# BYS_B register map
Vendor: Texas Instruments
Peripheral module from a debugger description file (folder omap5430_ES2_PUBLIC).
Registers are 32-bit, access per field, reset 0x0 unless marked. A register's access mark holds for its fields unless they carry their own. Offsets are as the file gives them; lines under a group give offsets from that group; [hi:lo] are bit positions; {n}, {i} and the like mark numbered series; 'fields as' and 'values as' point back to an identical list; <NAME> marks a mode.

## BYS_B
0x00 BYS_HL_REVISION ro reset not defined — IP Revision Identifier (X.Y.R) Used by software to track features, bugs, and compatibility
  [31:0] REVISION — IP Revision
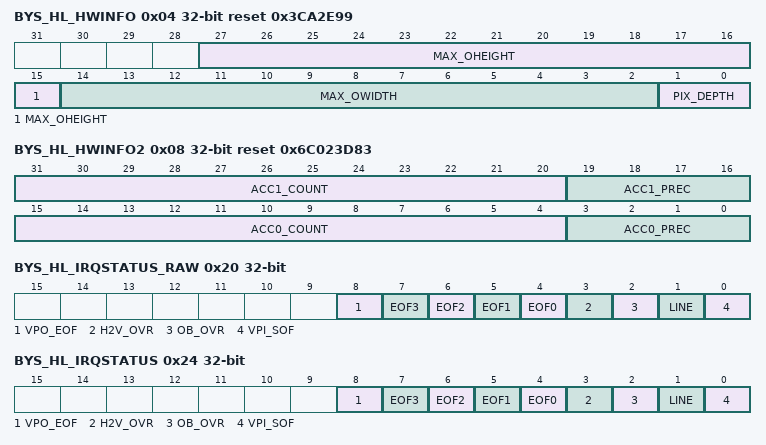
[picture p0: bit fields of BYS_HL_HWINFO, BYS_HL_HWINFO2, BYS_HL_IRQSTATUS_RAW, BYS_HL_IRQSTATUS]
0x04 BYS_HL_HWINFO ro reset 0x3CA2E99 — Information about the IP module's hardware configuration, i.e. typically the module's HDL generics (if any).
  [27:15] MAX_OHEIGHT — Maximum output height
  [14:2] MAX_OWIDTH — Maximum output width
  [1:0] PIX_DEPTH — Number of bits per pixel
    3=B16 (16); 2=B14 (14); 1=B12 (12); 0=B10 (10)
0x08 BYS_HL_HWINFO2 ro reset 0x6C023D83 — Information about the IP module's hardware configuration, i.e. typically the module's HDL generics (if any).
  [31:20] ACC1_COUNT — Number of entries = value*2
  [19:16] ACC1_PREC — Precision of accumulator 0 Number of Bits = value + 20
  [15:4] ACC0_COUNT — Number of entries = value*2
  [3:0] ACC0_PREC — Precision of accumulator 0 Number of Bits = value + 20
0x10 BYS_HL_SYSCONFIG — Clock management configuration
  [0] SOFTRESET rw — Software reset
    0=noaction; 1=reset (Initiate software reset); 1=pending (Reset (software or other) ongoing); 0=done (Reset done, no pending action)
0x20 BYS_HL_IRQSTATUS_RAW — Per-event raw interrupt status vector, line #0. Raw status is set even if event is not enabled.
  [all] fields
    1=pending (Event pending); 0=No event pending
  [8] VPO_EOF rw — Output video port end of frame event.
  [7] EOF3 rw
  [6] EOF2 rw
  [5] EOF1 rw — End of frame event of BSC pipe #1
  [4] EOF0 rw — End of frame event of BSC pipe #0
  [3] H2V_OVR rw — H2V FIFO overflow
  [2] OB_OVR rw — Output buffer overflow
  [1] LINE rw — Line event.
  [0] VPI_SOF rw — Start of frame event.
0x24 BYS_HL_IRQSTATUS — Per-event 'enabled' interrupt status vector, line #0. Enabled status isn't set unless event is enabled.
  [all] fields
    1=pending (Event pending); 0=noevent (No (enabled) event pending)
  [8] VPO_EOF rw — Output video port end of frame event.
  [7] EOF3 rw
  [6] EOF2 rw
  [5] EOF1 rw — End of frame event of BSC pipe #1
  [4] EOF0 rw — End of frame event of BSC pipe #0
  [3] H2V_OVR rw — H2V FIFO overflow
  [2] OB_OVR rw — Output buffer overflow
  [1] LINE rw — Line event.
  [0] VPI_SOF rw — Start of frame event.
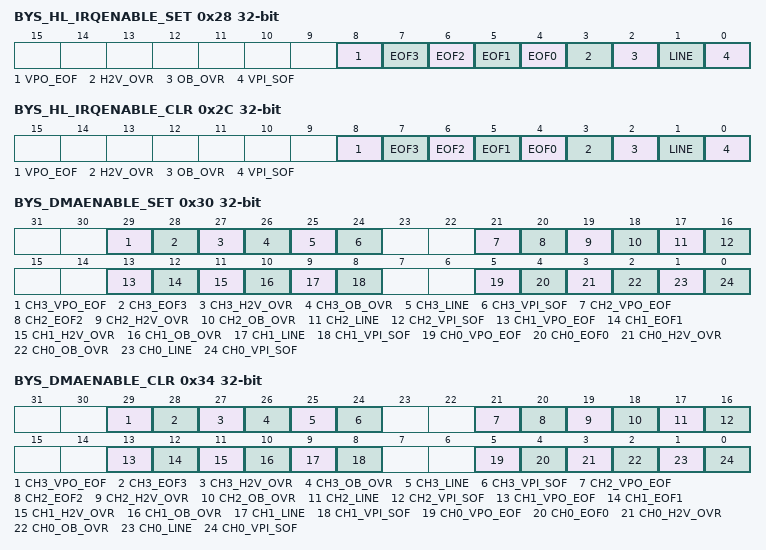
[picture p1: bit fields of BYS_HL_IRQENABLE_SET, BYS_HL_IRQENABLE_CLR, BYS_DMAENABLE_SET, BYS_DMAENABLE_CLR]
0x28 BYS_HL_IRQENABLE_SET access not given — Per-event interrupt enable bit vector Write 1 to set (enable interrupt). Readout equal to corresponding register.
  [all] fields
    0=noaction; 1=Enable interrupt; 1=enabled (Interrupt enabled); 0=disabled (Interrupt disabled (masked))
  [8] VPO_EOF — Output video port end of frame event. (access RW W1toSet)
  [7] EOF3 — (access RW W1toSet)
  [6] EOF2 — (access RW W1toSet)
  [5] EOF1 — End of frame event of BSC pipe #1 (access RW W1toSet)
  [4] EOF0 — End of frame event of BSC pipe #0 (access RW W1toSet)
  [3] H2V_OVR — H2V FIFO overflow (access RW W1toSet)
  [2] OB_OVR — Output buffer overflow (access RW W1toSet)
  [1] LINE — Line event (access RW W1toSet)
  [0] VPI_SOF — Start of frame event. (access RW W1toSet)
0x2C BYS_HL_IRQENABLE_CLR access not given — Per-event interrupt enable bit vector Write 1 to clear (disable interrupt). Readout equal to corresponding register.
  [all] fields
    0=noaction; 1=Disable interrupt; 1=enabled (Interrupt enabled); 0=disabled (Interrupt disabled (masked))
  [8] VPO_EOF — Output video port end of frame event. (access RW W1toClr)
  [7] EOF3 — (access RW W1toClr)
  [6] EOF2 — (access RW W1toClr)
  [5] EOF1 — End of frame event of BSC pipe #1 (access RW W1toClr)
  [4] EOF0 — End of frame event of BSC pipe #0 (access RW W1toClr)
  [3] H2V_OVR — H2V FIFO overflow (access RW W1toClr)
  [2] OB_OVR — Output buffer overflow. (access RW W1toClr)
  [1] LINE — Line event (access RW W1toClr)
  [0] VPI_SOF — Start of frame event. (access RW W1toClr)
0x30 BYS_DMAENABLE_SET — DMAREQUEST[0] Bits 7..0 DMAREQUEST[1] Bits 15..8 DMAREQUEST[2] Bits 23..16 DMAREQUEST[3] Bits 31..24 Write 1 to set (enable DMA request generation). Readout equal to corresponding register.
  [all] fields
    0=noaction; 1=Enable DMA; 1=enabled (DMA enabled); 0=disabled (DMA disabled)
  [29] CH3_VPO_EOF rw
  [28] CH3_EOF3 rw
  [27] CH3_H2V_OVR rw
  [26] CH3_OB_OVR rw
  [25] CH3_LINE rw
  [24] CH3_VPI_SOF rw
  [21] CH2_VPO_EOF rw
  [20] CH2_EOF2 rw
  [19] CH2_H2V_OVR rw
  [18] CH2_OB_OVR rw
  [17] CH2_LINE rw
  [16] CH2_VPI_SOF rw
  [13] CH1_VPO_EOF rw — Output video port end of frame event.
  [12] CH1_EOF1 rw — End of frame event of BSC pipe #1
  [11] CH1_H2V_OVR rw — H2V FIFO overflow
  [10] CH1_OB_OVR rw — Output buffer overflow.
  [9] CH1_LINE rw — Line event
  [8] CH1_VPI_SOF rw — Start of frame event.
  [5] CH0_VPO_EOF rw — Output video port end of frame event.
  [4] CH0_EOF0 rw — End of frame event of BSC pipe #0
  [3] CH0_H2V_OVR rw — H2V FIFO overflow
  [2] CH0_OB_OVR rw — Output buffer overflow.
  [1] CH0_LINE rw — Line event
  [0] CH0_VPI_SOF rw — Start of frame event.
0x34 BYS_DMAENABLE_CLR — DMAREQUEST[0] Bits 7..0 DMAREQUEST[1] Bits 15..8 DMAREQUEST[2] Bits 23..16 DMAREQUEST[3] Bits 31..24 Write 1 to clear (disable DMA request generation). Readout equal to corresponding register.
  [all] fields
    0=noaction; 1=enable (Disable DMA); 1=enabled (DMA enabled); 0=disabled (DMA disabled)
  [29] CH3_VPO_EOF rw
  [28] CH3_EOF3 rw
  [27] CH3_H2V_OVR rw
  [26] CH3_OB_OVR rw
  [25] CH3_LINE rw
  [24] CH3_VPI_SOF rw
  [21] CH2_VPO_EOF rw
  [20] CH2_EOF2 rw
  [19] CH2_H2V_OVR rw
  [18] CH2_OB_OVR rw
  [17] CH2_LINE rw
  [16] CH2_VPI_SOF rw
  [13] CH1_VPO_EOF rw — Output video port end of frame event.
  [12] CH1_EOF1 rw — End of frame event of BSC pipe #1
  [11] CH1_H2V_OVR rw — H2V FIFO overflow
  [10] CH1_OB_OVR rw — Output buffer overflow.
  [9] CH1_LINE rw — Line event
  [8] CH1_VPI_SOF rw — Start of frame event
  [5] CH0_VPO_EOF rw — Output video port end of frame event.
  [4] CH0_EOF0 rw — End of frame event of BSC pipe #0
  [3] CH0_H2V_OVR rw — H2V FIFO overflow
  [2] CH0_OB_OVR rw — Output buffer overflow.
  [1] CH0_LINE rw — Line event
  [0] CH0_VPI_SOF rw — Start of frame event
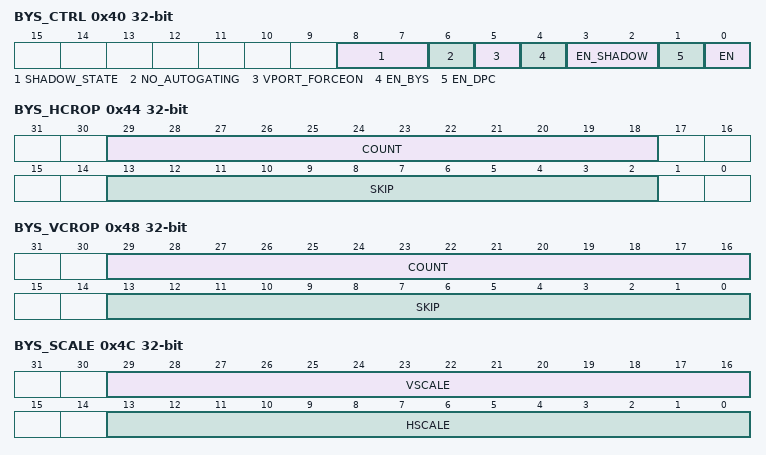
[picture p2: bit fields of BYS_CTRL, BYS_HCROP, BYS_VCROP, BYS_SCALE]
0x40 BYS_CTRL — Global control of the BYS module
  [8:7] SHADOW_STATE ro — Indicates the shadow register currently in use by the hardware. Register written by hardware. Software must check this before writing the BYS_CTRL register when BYS is active, so that a write into EN_SHADOW bit-field does not unintentially swap banks. Read 0x0: No shadowing. Hardware and software access bank 0. Read 0x1: No shadowing. Hardware and software access bank 1. Read 0x2: Shadowing. Hardware access bank 0 and software access bank 1. Read 0x3: Shadowing. Hardware access bank 1 and software access bank 0.
  [6] NO_AUTOGATING rw — Control internal autogating. ** DEBUG FEATURE **
    0=EN (Autogating enabled. This is the recommended behavior); 1=DIS (Autogating disabled Power consumption is increased. Only for debug purposes.)
  [5] VPORT_FORCEON rw — Controls gating of the output video port clock
    0=AUTO (Auto-gating. The video port clock is - enabled when pixels are sent - enabled 4 cycles before the 1st pixel is sent - disabled 4 pixels after the last pixel has been sent - disabled otherwise); 1=FREE (The pixel clock is free-running during blanking)
  [4] EN_BYS rw — Enable bayer scaler
    0=DISABLED (Disabled. Bayer scaler processing is bypassed (i.e. the output of the bayer scaler is the same than the bayer scaler input)); 1=ENABLED (Bayer scaler enabled)
  [3:2] EN_SHADOW rw — Controls register shadowing. Register written by software.
    0=OFF1 (No shadowing. Hardware and software access bank 0); 1=OFF2 (No shadowing. Hardware and software access bank 1); 3=ON2 (Shadowing. Hardware access bank 1 and software access bank 0.); 2=ON1 (Shadowing. Hardware access bank 0 and software access bank 1.)
  [1] EN_DPC rw — Enable defect pixel correction
    0=DIS (Defect pixel correction bypassed); 1=EN (Defect pixel correction enabled)
  [0] EN rw — Enable the BYS module
    0=DIS (Module disabled. Incoming pixels are ignored.); 1=EN (Enabled Incoming pixels will be processed.)
0x44 BYS_HCROP — Horizontal cropping settings. SKIP and COUNT positions must be multiples of 4 pixels.
  [29:18] COUNT rw — In steps of 4 pixels (i.e. write number of pixels to count divided by 4 into this register)
  [13:2] SKIP rw — In steps of 4 pixels (i.e. write number of pixels to skip divided by 4 into this register)
0x48 BYS_VCROP
  [29:16] COUNT rw — Vertical pixel count to be sent through
  [13:0] SKIP rw — Number of vertical skip of pixels
0x4C BYS_SCALE
  [29:16] VSCALE rw — Vertical down scaling
  [13:0] HSCALE rw — Horizantal down scaling
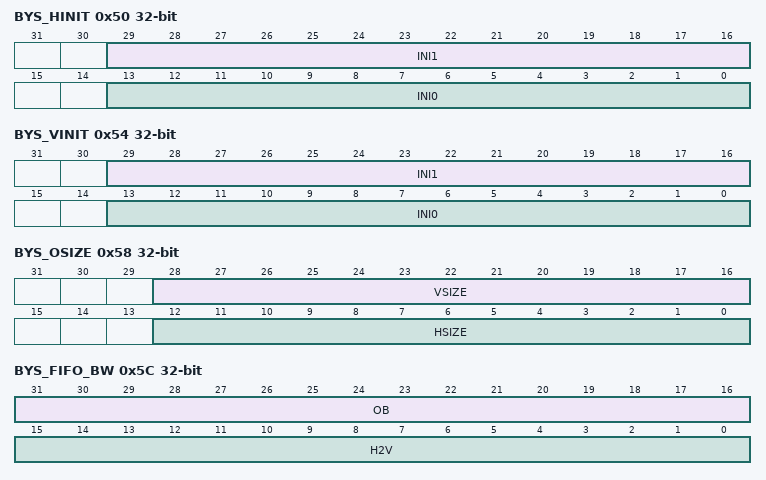
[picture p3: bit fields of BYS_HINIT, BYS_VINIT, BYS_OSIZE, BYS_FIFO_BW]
0x50 BYS_HINIT — Initial phase - horizontal scaler
  [29:16] INI1 rw — Horizantal Phase init for odd line
  [13:0] INI0 rw — Horizantal Phase init for even line
0x54 BYS_VINIT — Initial phase - vertical scaler
  [29:16] INI1 rw — vertical Phase init for odd line
  [13:0] INI0 rw — vertical Phase init for even line
0x58 BYS_OSIZE — Image size writen by the bayer scaler into the output FIFO.
  [28:16] VSIZE rw — Max output number of lines size Valid range: 1.. BYS_HL_HWINFO[27:15] MAX_OHEIGHT
  [12:0] HSIZE rw — Max output line size Valid range: 1.. BYS_HL_HWINFO[14:2] MAX_OWIDTH
0x5C BYS_FIFO_BW rw — Controls the data readout rate from the H2V and OUTPUT FIFOs
  [31:16] OB — Output buffer readout speed. U1.15 Valid range: 0.000030517578125 .. 1
  [15:0] H2V — H2V buffer readout speed. U1.15 Valid range: 0.000030517578125 .. 1
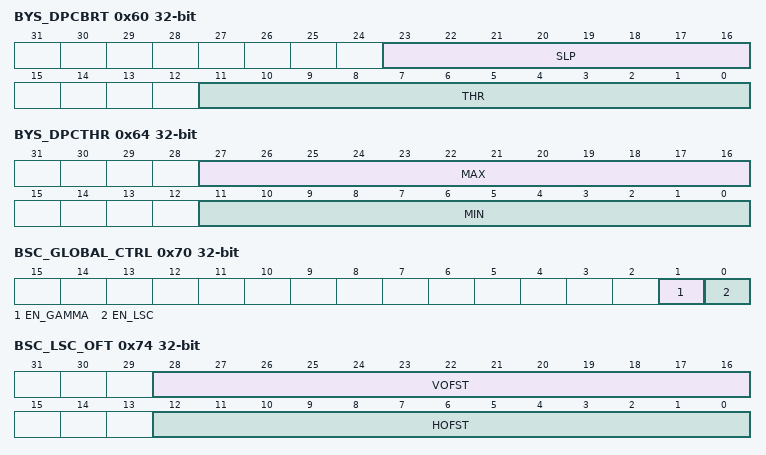
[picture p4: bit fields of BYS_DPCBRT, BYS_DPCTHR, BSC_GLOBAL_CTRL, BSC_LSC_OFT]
0x60 BYS_DPCBRT — Sets threshold adaptation based on brightness of neighborhood. This is a linear function
  [23:16] SLP rw — U8Q3 Slope of threshold increase
  [11:0] THR rw — U12 Minimum brightness level to begin increasing threshold
0x64 BYS_DPCTHR — Sets DPC detection threshold limits
  [27:16] MAX rw — Maximum DPC threshold value
  [11:0] MIN rw — Minimum DPC threshold value.
0x6C BYS_LINE — Line number for the LINE IRQ.
  [12:0] LINE rw — Valid range 0..BYS_HL_HWINFO[27:15] MAX_OHEIGHT
0x70 BSC_GLOBAL_CTRL — Global control of the BSC pipe
  [1] EN_GAMMA rw — Enable gamma correction
    0=ZERO (Disabled. The module is bypassed: PIXOUT=PIXIN); 1=ONE (Enabled.)
  [0] EN_LSC rw — Enable lens shading correction
    0=ZERO (Disabled The module is bypassed: PIXOUT=PIXIN); 1=ONE (Enabled)
0x74 BSC_LSC_OFT — LSC OFT
  [28:16] VOFST rw — Vertical offset
  [12:0] HOFST rw — Horizontal offset
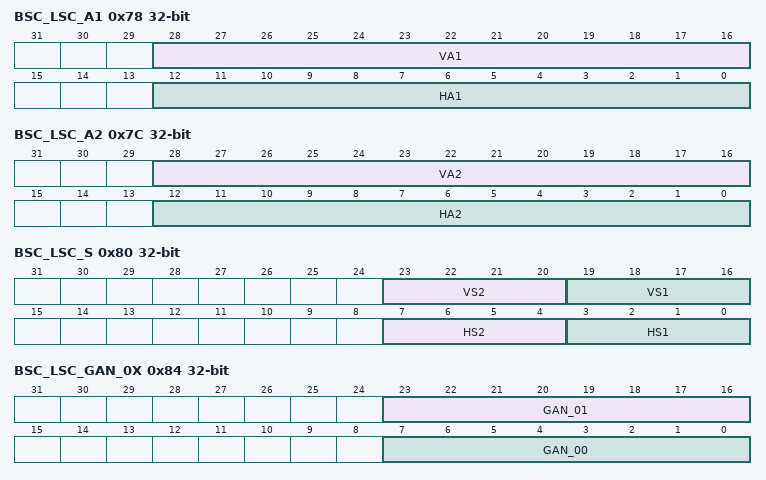
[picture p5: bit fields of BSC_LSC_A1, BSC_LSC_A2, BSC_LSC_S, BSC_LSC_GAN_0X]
0x78 BSC_LSC_A1 — Linear coefficients
  [28:16] VA1 rw — A1 Vertical linear coefficient
  [12:0] HA1 rw — A1 Horizontal linear coefficient
0x7C BSC_LSC_A2 — Quadratic coefficients
  [28:16] VA2 rw — A2 Vertical quadratic coefficient
  [12:0] HA2 rw — A2 Horizontal quadratic coefficient
0x80 BSC_LSC_S — Shift lenghts
  [23:20] VS2 rw — S2 Vertical quadratic shift length
  [19:16] VS1 rw — S1 Vertical linear shift length
  [7:4] HS2 rw — S2 Horizontal quadratic shift length
  [3:0] HS1 rw — S1 Horizontal linear shift length
0x84 BSC_LSC_GAN_0X — Gain Adjustments 0
  [23:16] GAN_01 rw — Gain Adjustment 01
  [7:0] GAN_00 rw — Gain Adjustment 00
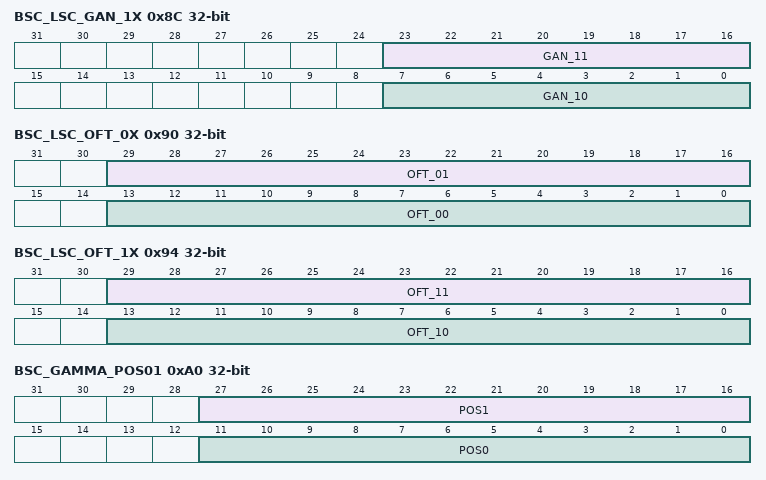
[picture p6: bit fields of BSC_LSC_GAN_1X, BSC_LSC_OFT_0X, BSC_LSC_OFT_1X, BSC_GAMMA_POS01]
0x8C BSC_LSC_GAN_1X — Gain Adjustments 1
  [23:16] GAN_11 rw — Gain Adjustment 11
  [7:0] GAN_10 rw — Gain Adjustment 10
0x90 BSC_LSC_OFT_0X — Total offsets 0
  [29:16] OFT_01 rw — Total Offset for 01 Valid range = -4096..+4095
  [13:0] OFT_00 rw — Total Offset for 00 Valid range = -4096..+4095
0x94 BSC_LSC_OFT_1X — Total offsets 1
  [29:16] OFT_11 rw — Total Offset for 11 Valid range = -4096..+4095
  [13:0] OFT_10 rw — Total Offset for 10 Valid range = -4096..+4095
0x98 BSC_LSC_SHF — S0 Gain Shift Length
  [3:0] VAL rw — LSC SHF
0x9C BSC_LSC_MAX — Gain Maximum Value
  [8:0] VAL rw — LSC MAX
0xA0 BSC_GAMMA_POS01 — Pixel positions
  [27:16] POS1 rw — Second segment position parameter
  [11:0] POS0 ro — First segment position parameter
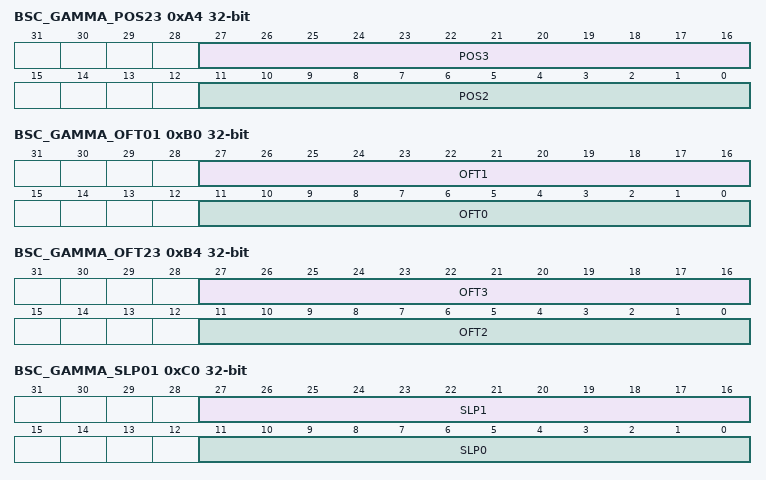
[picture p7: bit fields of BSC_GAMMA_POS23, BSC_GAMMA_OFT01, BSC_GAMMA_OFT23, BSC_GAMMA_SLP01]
0xA4 BSC_GAMMA_POS23 — Pixel positions
  [27:16] POS3 rw — Fourth segment position parameter
  [11:0] POS2 rw — Third segment position parameter
0xB0 BSC_GAMMA_OFT01 — Pixel offsets
  [27:16] OFT1 rw — Pixel offset for POS1
  [11:0] OFT0 rw — Pixel offset for POS0
0xB4 BSC_GAMMA_OFT23 — Pixel offsets
  [27:16] OFT3 rw — Pixel offset for POS3
  [11:0] OFT2 rw — Pixel offset for POS2
0xC0 BSC_GAMMA_SLP01 — Pixel slopes
  [27:16] SLP1 rw — Pixel slope for POS1
  [11:0] SLP0 rw — Pixel slope for POS0
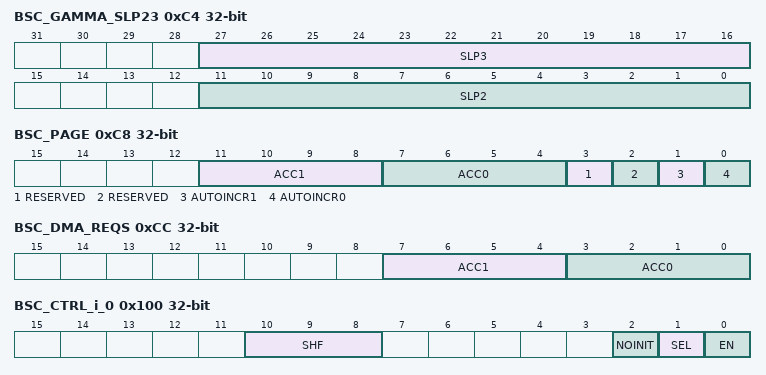
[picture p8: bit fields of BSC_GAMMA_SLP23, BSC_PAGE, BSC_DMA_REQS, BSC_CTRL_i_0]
0xC4 BSC_GAMMA_SLP23 — Pixel slopes
  [27:16] SLP3 rw — Pixel slope for POS3
  [11:0] SLP2 rw — Pixel slope for POS2
0xC8 BSC_PAGE — Controls access to BSC memories. Only 512 accumulator values per pipe are mapped into the addres space. The page ID is automatically incremented when the last location of a page is accesses. Alternatively, software directly chose the page number for each accumulator.
  [11:8] ACC1 rw — Page for accumulator pipe #1
  [7:4] ACC0 rw — Page for accumulator pipe #0
  [3] RESERVED ro — enum=DIS . enum=EN .
  [2] RESERVED ro — enum=DIS . enum=EN .
  [1] AUTOINCR1 rw — Enables automatic page increment for the corresponding accumulator pipe #1 when the last location has been accessed
    0=DIS (Disabled); 1=EN (Enabled)
  [0] AUTOINCR0 rw — Enables automatic page increment for the corresponding accumulator pipe #0 when the last location has been accessed
    0=DIS (Disabled); 1=EN (Enabled)
0xCC BSC_DMA_REQS — Number of DMA requests to generate per pipeline minus 1
  [7:4] ACC1 rw — Number of DMA requests for accumulator pipe #1
  [3:0] ACC0 rw — Number of DMA requests for accumulator pipe #0
0x100 BSC_CTRL_i_0 — Global control of the BSC module
  [10:8] SHF rw — The down shift value before accumulation. Range: 0-7
  [2] NOINIT rw — Don't initialize accumulators when set.
    0=INIT (Reset accumulators every frame); 1=NOINIT (Don't reset accumulators. Add new data to data already in the memory)
  [1] SEL rw — Select accumulator organization in the memory
    0=COl (Column vector mode. ID = floor((h-HSKIP)/HSIZE)+HCNT*floor((v-VSKIP)/VSIZE)); 1=ROW (Row vector mode ID = VCNT*floor((h-HSKIP)/HSIZE)+floor((v-VSKIP)/VSIZE))
  [0] EN rw — Enable statistics collection
    0=ZERO (Disabled. No statistics are collected for this pipeline. The memory content is left unchanged.); 1=ONE (Enabled.)
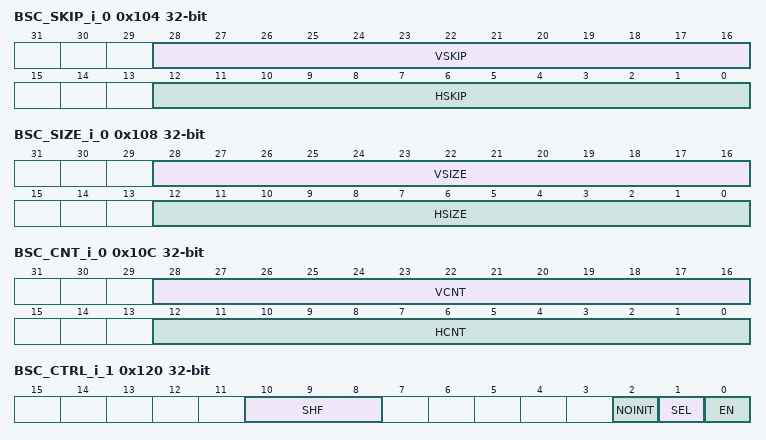
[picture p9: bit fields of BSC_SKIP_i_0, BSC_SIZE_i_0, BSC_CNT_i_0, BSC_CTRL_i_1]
0x104 BSC_SKIP_i_0 — Position of the top left corner analyzed by BSC
  [28:16] VSKIP rw — The V position of left-top of the sampled frame Valid range: 0.. (BYS_HL_HWINFO[27:15] MAX_OHEIGHT - 1)
  [12:0] HSKIP rw — The H position of left-top of the sampled frame Valid range: 0.. (BYS_HL_HWINFO[14:2] MAX_OWIDTH - 1)
0x108 BSC_SIZE_i_0 — Bin size
  [28:16] VSIZE rw — The height of the rectangle Valid range: 1.. BYS_HL_HWINFO[27:15] MAX_OHEIGHT
  [12:0] HSIZE rw — The width of the rectangle Valid range: If BSC_CTRL_i[1] SEL = 0: 1.. BYS_HL_HWINFO[14:2] MAX_OWIDTH If BSC_CTRL_i[1] SEL = 1: 2.. BYS_HL_HWINFO[14:2] MAX_OWIDTH
0x10C BSC_CNT_i_0 — Number of bins in each direction software must ensure that HCNT*VCNT <= [] ACCi_COUNT, where i = 0 to 1
  [28:16] VCNT rw — Number of bins in the vertical direction (the vertical number of rectangles in the frame) Valid range: 1.. BYS_HL_HWINFO[27:15] MAX_OHEIGHT
  [12:0] HCNT rw — Number of bins in the horizontal direction (the horizontal number of rectangles in the frame) Valid range: 1.. BYS_HL_HWINFO[14:2] MAX_OWIDTH
0x120 BSC_CTRL_i_1 — Global control of the BSC module
  fields as BSC_CTRL_i_0
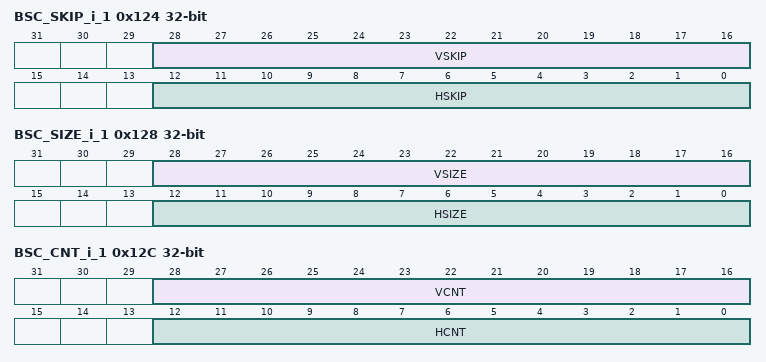
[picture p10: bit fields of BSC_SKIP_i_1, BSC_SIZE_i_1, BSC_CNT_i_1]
0x124 BSC_SKIP_i_1 — Position of the top left corner analyzed by BSC
  fields as BSC_SKIP_i_0
0x128 BSC_SIZE_i_1 — Bin size
  fields as BSC_SIZE_i_0
0x12C BSC_CNT_i_1 — Number of bins in each direction software must ensure that HCNT*VCNT <= [] ACCi_COUNT, where i = 0 to 1
  fields as BSC_CNT_i_0
